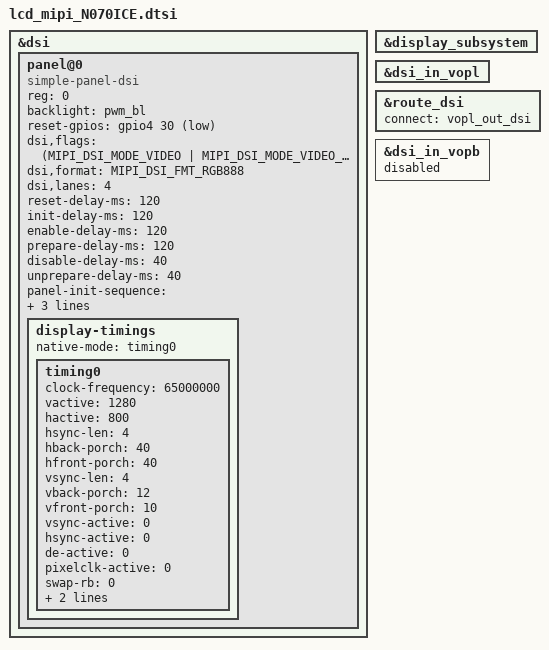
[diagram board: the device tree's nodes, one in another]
&dsi {
	status = "okay";
	//rockchip,lane-rate = <424>;
	panel@0 {
		compatible ="simple-panel-dsi";
		reg = <0>;
		backlight = <&pwm_bl>;
		//power-supply = <&vcc_lcd>;
		//enable-gpios = <&gpio1 13 GPIO_ACTIVE_HIGH>;
		reset-gpios = <&gpio4 30 GPIO_ACTIVE_LOW>;//gpio4_d6
		dsi,flags = <(MIPI_DSI_MODE_VIDEO | MIPI_DSI_MODE_VIDEO_BURST |
			      MIPI_DSI_MODE_LPM)>;
		dsi,format = <MIPI_DSI_FMT_RGB888>;
		dsi,lanes = <4>;
		reset-delay-ms = <120>;//120
		init-delay-ms = <120>;//120
		enable-delay-ms = <120>;//120
		prepare-delay-ms = <120>;//120
		disable-delay-ms = <40>;//120
		unprepare-delay-ms = <40>;
		status = "okay";

		panel-init-sequence = [
			39 00 05 FF AA 55 A5 80
			39 00 03 6F 11 00
			39 00 03 F7 20 00
			15 00 02 6F 06
			15 00 02 F7 A0
			15 00 02 6F 19
			15 00 02 F7 12
			39 00 06 F0 55 AA 52 08 00
			39 00 03 C8 10 2D
			39 00 03 B1 6C 01
			15 00 02 B6 08
			15 00 02 6F 02
			15 00 02 B8 08
			39 00 03 BB 54 44
			39 00 03 BC 05 05
			15 00 02 C7 01
			39 00 06 BD 02 B0 0C 0A 00
			39 00 06 F0 55 AA 52 08 01
			39 00 03 B0 05 05
			39 00 03 B1 05 05
			39 00 03 BC 3A 00
			39 00 03 BD 3E 00
			15 00 02 CA 00
			15 00 02 C0 04
			15 00 02 BE 80
			39 00 03 B3 19 19
			39 00 03 B4 12 12
			39 00 03 B9 24 24
			39 00 03 BA 14 14
			39 00 06 F0 55 AA 52 08 02
			15 00 02 EE 02
			39 00 05 EF 09 06 15 18
			39 00 07 B0 00 00 00 13 00 2B
			15 00 02 6F 06
			39 00 07 B0 00 40 00 4E 00 69
			15 00 02 6F 0C
			39 00 05 B0 00 83 00 B5
			39 00 07 B1 00 DF 01 20 01 53
			15 00 02 6F 06
			39 00 07 B1 01 A6 01 EA 01 EC
			15 00 02 6F 0C
			39 00 05 B1 02 2C 02 73
			39 00 07 B2 02 A0 02 DE 03 0A
			15 00 02 6F 06
			39 00 07 B2 03 45 03 69 03 90
			15 00 02 6F 0C
			39 00 05 B2 03 A2 03 BF
			39 00 05 B3 03 D2 03 FF
			39 00 07 BC 00 00 00 13 00 2B
			15 00 02 6F 06
			39 00 07 BC 00 42 00 50 00 6B
			15 00 02 6F 0C
			39 00 05 BC 00 87 00 BB
			39 00 07 BD 00 E7 01 28 01 5B
			15 00 02 6F 06
			39 00 07 BD 01 AC 01 F0 01 F2
			15 00 02 6F 0C
			39 00 05 BD 02 32 02 77
			39 00 07 BE 02 A4 02 E2 03 0C
			15 00 02 6F 06
			39 00 07 BE 03 47 03 6B 03 92
			15 00 02 6F 0C
			39 00 05 BE 03 A4 03 BF
			39 00 05 BF 03 D2 03 FF
			39 00 06 F0 55 AA 52 08 06
			39 00 03 B0 00 17
			39 00 03 B1 16 15
			39 00 03 B2 14 13
			39 00 03 B3 12 11
			39 00 03 B4 10 2D
			39 00 03 B5 01 08
			39 00 03 B6 09 31
			39 00 03 B7 31 31
			39 00 03 B8 31 31
			39 00 03 B9 31 31
			39 00 03 BA 31 31
			39 00 03 BB 31 31
			39 00 03 BC 31 31
			39 00 03 BD 31 09
			39 00 03 BE 08 01
			39 00 03 BF 2D 10
			39 00 03 C0 11 12
			39 00 03 C1 13 14
			39 00 03 C2 15 16
			39 00 03 C3 17 00
			39 00 03 E5 31 31
			39 00 03 C4 00 17
			39 00 03 C5 16 15
			39 00 03 C6 14 13
			39 00 03 C7 12 11
			39 00 03 C8 10 2D
			39 00 03 C9 01 08
			39 00 03 CA 09 31
			39 00 03 CB 31 31
			39 00 03 CC 31 31
			39 00 03 CD 31 31
			39 00 03 CE 31 31
			39 00 03 CF 31 31
			39 00 03 D0 31 31
			39 00 03 D1 31 09
			39 00 03 D2 08 01
			39 00 03 D3 2D 10
			39 00 03 D4 11 12
			39 00 03 D5 13 14
			39 00 03 D6 15 16
			39 00 03 D7 17 00
			39 00 03 E6 31 31
			39 00 06 D8 00 00 00 00 00
			39 00 06 D9 00 00 00 00 00
			15 00 02 E7 00
			39 00 06 F0 55 AA 52 08 03
			39 00 03 B0 20 00
			39 00 03 B1 20 00
			39 00 06 B2 05 00 42 00 00
			39 00 06 B6 05 00 42 00 00
			39 00 06 BA 53 00 42 00 00
			39 00 06 BB 53 00 42 00 00
			15 00 02 C4 40
			39 00 03 B0 01 01
			39 00 03 B1 01 01
			39 00 06 F0 55 AA 52 08 05
			39 00 03 B0 17 06
			15 00 02 B8 00
			39 00 06 BD 03 01 01 00 01
			39 00 03 B1 17 06
			39 00 03 B9 00 01
			39 00 03 B2 17 06
			39 00 03 BA 00 01
			39 00 03 B3 17 06
			39 00 03 BB 0A 00
			39 00 03 B4 17 06
			39 00 03 B5 17 06
			39 00 03 B6 14 03
			39 00 03 B7 00 00
			39 00 03 BC 02 01
			15 00 02 C0 05
			15 00 02 C4 A5
			39 00 03 C8 03 30
			39 00 03 C9 03 51
			39 00 06 D1 03 00 05 03 00
			39 00 06 D2 03 00 05 09 00
			15 00 02 E5 02
			15 00 02 E6 02
			15 00 02 E7 02
			15 00 02 E9 02
			15 00 02 ED 03
			05 78 01 11
			05 78 01 29
		];

		panel-exit-sequence = [
			05 78 01 28
			05 78 01 10
		];

		display-timings{
			native-mode = <&timing0>;
			timing0: timing0 {
				clock-frequency = <65000000>;
				vactive = <1280>;
				hactive = <800>;
				hsync-len = <4>;
				hback-porch = <40>;
				hfront-porch = <40>;
				vsync-len = <4>;
				vback-porch = <12>;
				vfront-porch = <10>;
				vsync-active = <0>;
				hsync-active = <0>;
				de-active = <0>;
				pixelclk-active = <0>;
				swap-rb = <0>;
				swap-rg = <0>;
				swap-gb = <0>;
			};
		};

	};
};

&display_subsystem{
	status = "okay";
};

&dsi_in_vopl {
	//status = "disabled";
	status = "okay";
};

&route_dsi {
	status = "okay";
	//connect = <&vopb_out_dsi>;
	connect = <&vopl_out_dsi>;
};

&dsi_in_vopb {
	//status = "okay";
	status = "disabled";
};
